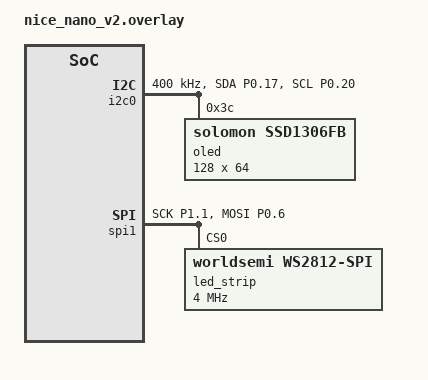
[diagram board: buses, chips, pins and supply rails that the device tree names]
/**
 * Generated by Shield Wizard for ZMK
 * Applies to part "right" with controller "nice_nano_v2"
 */

// pin control for i2c0
// - SDA on D2
// - SCL on D3
&pinctrl {
    /* configuration for i2c0 device, default state */
    i2c0_default: i2c0_default {
        group1 {
            psels = <NRF_PSEL(TWIM_SDA, 0, 17)>,
                    <NRF_PSEL(TWIM_SCL, 0, 20)>;
        };
    };
    /* configuration for i2c0 device, sleep state */
    i2c0_sleep: i2c0_sleep {
        group1 {
            psels = <NRF_PSEL(TWIM_SDA, 0, 17)>,
                    <NRF_PSEL(TWIM_SCL, 0, 20)>;
            low-power-enable;
        };
    };
};
&i2c0 {
   // compatible = "nordic,nrf-twim";
    status = "okay";
    pinctrl-0 = <&i2c0_default>;
    pinctrl-1 = <&i2c0_sleep>;
    pinctrl-names = "default", "sleep";
    clock-frequency = <I2C_BITRATE_FAST>;
};

// devices on i2c0

/*
 * OLED: 0.96" 128x64 SSD1306, SAME panel as the left half.
 *
 * This node used to be 128x32 with segment-remap / com-invdir /
 * com-sequential / inversion-on. That was wrong: this value came in with
 * the initial bulk commit and was never verified against the real board,
 * and 128x32 is the 0.91" panel, not the 0.96" one that is actually
 * fitted. Both halves now carry an identical panel definition, so the
 * only thing that can differ between them is their content.
 *
 * If the right screen ever comes up mirrored or upside down, the cause
 * is the mounting direction, not the size -- re-add "segment-remap;"
 * and "com-invdir;" here (that flips both axes) and nothing else.
 */
&i2c0 {
    oled: ssd1306@3c {
        compatible = "solomon,ssd1306fb";
        reg = <0x3c>;
        width = <128>;
        height = <64>;
        segment-offset = <0>;
        page-offset = <0>;
        display-offset = <0>;
        multiplex-ratio = <63>;
        prechargep = <0x22>;
    };
};
/ {
    chosen {
        zephyr,display = &oled;
    };
};

// pin control for spi1
// - SCK on P1.01
// - MOSI on D1
&pinctrl {
    /* configuration for spi1 device, default state */
    spi1_default: spi1_default {
        group1 {
            psels = <NRF_PSEL(SPIM_SCK, 1, 1)>,
                    <NRF_PSEL(SPIM_MOSI, 0, 6)>;
        };
    };
    /* configuration for spi1 device, sleep state */
    spi1_sleep: spi1_sleep {
        group1 {
            psels = <NRF_PSEL(SPIM_SCK, 1, 1)>,
                    <NRF_PSEL(SPIM_MOSI, 0, 6)>;
            low-power-enable;
        };
    };
};
&spi1 {
    compatible = "nordic,nrf-spim";
    status = "okay";
    pinctrl-0 = <&spi1_default>;
    pinctrl-1 = <&spi1_sleep>;
    pinctrl-names = "default", "sleep";
};

// devices on spi1

#include <dt-bindings/led/led.h>
&spi1 {
    led_strip: ws2812@0 {
        compatible = "worldsemi,ws2812-spi";
        reg = <0>;
        spi-max-frequency = <4000000>;

        chain-length = <29>;
        spi-one-frame = <0x70>;
        spi-zero-frame = <0x40>;
        color-mapping = <LED_COLOR_ID_GREEN
                         LED_COLOR_ID_RED
                         LED_COLOR_ID_BLUE>;
    };
};
/ {
    chosen {
        zmk,underglow = &led_strip;
    };
};
